# LPC5410x register map
File version: 0.4
CPU: CM4 r0p0, little endian, no MPU, no FPU, 0x3 interrupt priority bits, 0x0 interrupts
Registers are 32-bit, read-write, reset 0x0 unless marked. A register's access mark holds for its fields unless they carry their own. Offsets are from the block's base; [hi:lo] are bit positions; {n}, {i} and the like mark numbered series.

## SYSCON — System configuration
Base 0x40000000
0x00 SYSMEMREMAP — System memory remap
  [1:0] MAP — System memory remap. Value 0x3 is reserved.
    0=BOOT_LOADER_MODE (Boot Loader Mode. Interrupt vectors are re-mapped to Boot ROM.); 1=USER_RAM_MODE (User RAM Mode. Interrupt vectors are re-mapped to Static RAM.); 2=USER_FLASH_MODE (User Flash Mode. Interrupt vectors are not re-mapped and reside in Flash.)
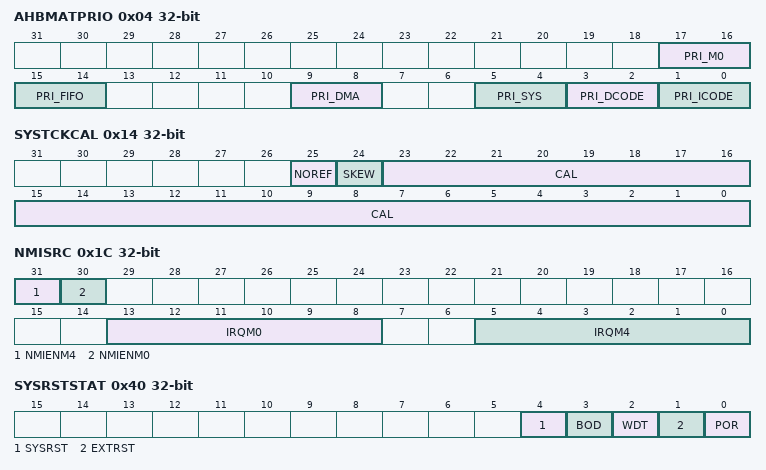
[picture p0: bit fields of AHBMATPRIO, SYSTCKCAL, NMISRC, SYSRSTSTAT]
0x04 AHBMATPRIO — AHB multilayer matrix priority control
  [17:16] PRI_M0 — Cortex-M0+ bus priority.
  [15:14] PRI_FIFO — System FIFO bus priority
  [9:8] PRI_DMA — DMA controller priority.
  [5:4] PRI_SYS — System bus priority.
  [3:2] PRI_DCODE — D-Code bus priority.
  [1:0] PRI_ICODE — I-Code bus priority. Should be lower than PRI_DCODE for proper operation.
0x14 SYSTCKCAL — System tick counter calibration
  [25] NOREF — Initial value for the Systick timer.
  [24] SKEW — Initial value for the Systick timer.
  [23:0] CAL — System tick timer calibration value.
0x1C NMISRC — NMI Source Select
  [31] NMIENM4 — Write a 1 to this bit to enable the Non-Maskable Interrupt (NMI) source selected by IRQM4.
  [30] NMIENM0 — Write a 1 to this bit to enable the Non-Maskable Interrupt (NMI) source selected by IRQM0.
  [13:8] IRQM0 — The IRQ number of the interrupt that acts as the Non-Maskable Interrupt (NMI) for the Cortex-M0+, if enabled by NMIENM0.
  [5:0] IRQM4 — The IRQ number of the interrupt that acts as the Non-Maskable Interrupt (NMI) for the Cortex-M4, if enabled by NMIENM4.
0x20 ASYNCAPBCTRL reset 0x1 — Asynchronous APB Control
  [0] ENABLE — Enables the asynchronous APB bridge and subsystem.
    0=DISABLED (Disabled. Asynchronous APB bridge is disabled.); 1=ENABLED (Enabled. Asynchronous APB bridge is enabled.)
0x40 SYSRSTSTAT — System reset status register
  [4] SYSRST — Status of the software system reset
    0=NO_SYSTEM_RESET_DETE (No System reset detected); 1=SYSTEM_RESET_DETECTE (System reset detected. Writing a one clears this reset.)
  [3] BOD — Status of the Brown-out detect reset
    0=NO_BOD_RESET_DETECTE (No BOD reset detected); 1=BOD_RESET_DETECTED (BOD reset detected. Writing a one clears this reset.)
  [2] WDT — Status of the Watchdog reset
    0=NO_WDT_RESET_DETECTE (No WDT reset detected); 1=WDT_RESET_DETECTED (WDT reset detected. Writing a one clears this reset.)
  [1] EXTRST — Status of the external RESET pin. External reset status.
    0=NO_RESET_EVENT_DETEC (No reset event detected.); 1=RESET_DETECTED (Reset detected. Writing a one clears this reset.)
  [0] POR — POR reset status
    0=NO_POR_DETECTED; 1=POR_DETECTED (POR detected. Writing a one clears this reset.)
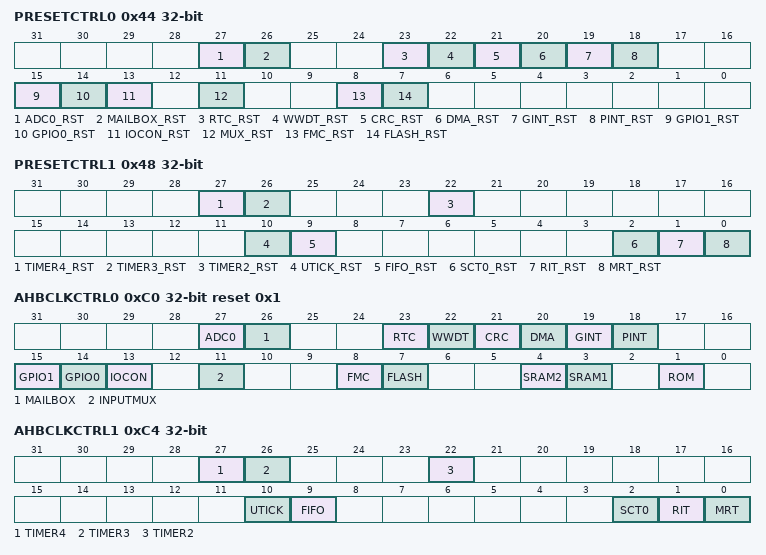
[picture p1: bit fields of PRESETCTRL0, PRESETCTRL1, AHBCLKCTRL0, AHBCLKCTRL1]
0x44 PRESETCTRL0 — Peripheral reset control 0
  [27] ADC0_RST — ADC0 reset control. 0 = Clear reset to this function. 1 = Assert reset to this function.
  [26] MAILBOX_RST — Mailbox reset control. 0 = Clear reset to this function. 1 = Assert reset to this function.
  [23] RTC_RST — RTC reset control. 0 = Clear reset to this function. 1 = Assert reset to this function.
  [22] WWDT_RST — Watchdog timer reset control. 0 = Clear reset to this function. 1 = Assert reset to this function.
  [21] CRC_RST — CRC generator reset control. 0 = Clear reset to this function. 1 = Assert reset to this function.
  [20] DMA_RST — DMA reset control. 0 = Clear reset to this function. 1 = Assert reset to this function.
  [19] GINT_RST — Grouped interrupt (GINT) reset control. 0 = Clear reset to this function. 1 = Assert reset to this function.
  [18] PINT_RST — Pin interrupt (PINT) reset control. 0 = Clear reset to this function. 1 = Assert reset to this function.
  [15] GPIO1_RST — GPIO1 reset control. 0 = Clear reset to this function. 1 = Assert reset to this function.
  [14] GPIO0_RST — GPIO0 reset control. 0 = Clear reset to this function. 1 = Assert reset to this function.
  [13] IOCON_RST — IOCON reset control. 0 = Clear reset to this function. 1 = Assert reset to this function.
  [11] MUX_RST — Input mux reset control. 0 = Clear reset to this function. 1 = Assert reset to this function.
  [8] FMC_RST — Flash accelerator reset control. 0 = Clear reset to this function. 1 = Assert reset to this function.
  [7] FLASH_RST — Flash controller reset control. 0 = Clear reset to this function. 1 = Assert reset to this function.
0x48 PRESETCTRL1 — Peripheral reset control 1
  [27] TIMER4_RST — Timer 4 reset control. 0 = Clear reset to this function. 1 = Assert reset to this function.
  [26] TIMER3_RST — Timer 3 reset control. 0 = Clear reset to this function. 1 = Assert reset to this function.
  [22] TIMER2_RST — Timer 2 reset control. 0 = Clear reset to this function. 1 = Assert reset to this function.
  [10] UTICK_RST — Micro-tick Timer reset control. 0 = Clear reset to this function. 1 = Assert reset to this function.
  [9] FIFO_RST — System FIFO reset control. 0 = Clear reset to this function. 1 = Assert reset to this function.
  [2] SCT0_RST — State configurable timer 0 (SCT0) reset control. 0 = Clear reset to this function. 1 = Assert reset to this function.
  [1] RIT_RST — Repetitive interrupt timer (RIT) reset control. 0 = Clear reset to this function. 1 = Assert reset to this function.
  [0] MRT_RST — Multi-rate timer (MRT) reset control. 0 = Clear reset to this function. 1 = Assert reset to this function.
0x4C PRESETCTRLSET0 wo reset not defined — Set bits in PRESETCTRL0
  [31:0] RST_SET0 — Writing ones to this register sets the corresponding bit or bits in the PRESETCTRL0 register, if they are implemented. Bits that do not correspond to defined bits in PRESETCTRL0 are reserved and only zeroes should be written to them.
0x50 PRESETCTRLSET1 wo reset not defined — Set bits in PRESETCTRL1
  [31:0] RST_SET1 — Writing ones to this register sets the corresponding bit or bits in the PRESETCTRL1 register, if they are implemented. Bits that do not correspond to defined bits in PRESETCTRL1 are reserved and only zeroes should be written to them.
0x54 PRESETCTRLCLR0 wo reset not defined — Clear bits in PRESETCTRL0
  [31:0] RST_CLR0 — Writing ones to this register clears the corresponding bit or bits in the PRESETCTRL0 register, if they are implemented. Bits that do not correspond to defined bits in PRESETCTRL0 are reserved and only zeroes should be written to them.
0x58 PRESETCTRLCLR1 wo reset not defined — Clear bits in PRESETCTRL1
  [31:0] RST_CLR1 — Writing ones to this register clears the corresponding bit or bits in the PRESETCTRL1 register, if they are implemented. Bits that do not correspond to defined bits in PRESETCTRL1 are reserved and only zeroes should be written to them.
0x5C PIOPORCAP0 ro reset not defined — POR captured PIO status 0
  [31:0] PIOPORSTAT — State of PIO0_31 through PIO0_0 at power-on reset
0x60 PIOPORCAP1 ro reset not defined — POR captured PIO status 1
  [31:0] PIOPORSTAT — State of PIO1_31 through PIO1_0 at power-on reset
0x68 PIORESCAP0 ro reset not defined — Reset captured PIO status 0
  [31:0] PIORESSTAT — State of PIO0_31 through PIO0_0 for resets other than power-on reset.
0x6C PIORESCAP1 ro reset not defined — Reset captured PIO status 1
  [31:0] PIORESSTAT — State of PIO1_31 through PIO1_0 for resets other than power-on reset.
0x80 MAINCLKSELA — Main clock source select A
  [1:0] SEL — Clock source for main clock source selector A
    0=IRC_OSCILLATOR; 1=CLKIN; 2=WATCHDOG_OSCILLATOR
0x84 MAINCLKSELB — Main clock source select B
  [1:0] SEL — Clock source for main clock source selector B. Selects the clock source for the main clock.
    0=MAINCLKSELA (MAINCLKSELA. Use the clock source selected in MAINCLKSELA register.); 1=SYSTEM_PLL_INPUT; 2=SYSTEM_PLL_OUTPUT; 3=RTC_OSC_OUTPUT (RTC osc output. RTC oscillator 32 kHz output.)
0x8C ADCCLKSEL — ADC clock source select
  [1:0] SEL — ADC clock source.
    0=MAIN_CLOCK; 1=SYSTEM_PLL_OUTPUT; 2=IRC_OSCILLATOR
0x94 CLKOUTSELA — CLKOUT clock source select A
  [1:0] SEL — CLKOUT clock source
    0=MAIN_CLOCK; 1=CLKIN; 2=WATCHDOG_OSCILLATOR; 3=IRC_OSCILLATOR
0x98 CLKOUTSELB — CLKOUT clock source select B
  [1:0] SEL — CLKOUT clock source
    0=CLKOUTSELA (CLKOUTSELA. Clock source selected in the CLKOUTSELA register.); 3=RTC_32_KHZ_CLOCK
0xA0 SYSPLLCLKSEL — PLL clock source select
  [1:0] SEL — System PLL clock source
    0=IRC_OSCILLATOR; 1=CLKIN; 2=WATCHDOG_OSCILLATOR; 3=RTC_32_KHZ_CLOCK
0xC0 AHBCLKCTRL0 reset 0x1 — AHB Clock control 0
  [27] ADC0 — Enables the clock for the ADC0 register interface. 0 = Disable; 1 = Enable.
  [26] MAILBOX — Enables the clock for the Mailbox. 0 = Disable; 1 = Enable.
  [23] RTC — Enables the clock for the RTC. 0 = Disable; 1 = Enable.
  [22] WWDT — Enables the clock for the Watchdog Timer. 0 = Disable; 1 = Enable.
  [21] CRC — Enables the clock for the CRC engine. 0 = Disable; 1 = Enable.
  [20] DMA — Enables the clock for the DMA controller. 0 = Disable; 1 = Enable.
  [19] GINT — Enables the clock for the grouped pin interrupt block. 0 = Disable; 1 = Enable.
  [18] PINT — Enables the clock for the pin interrupt block.0 = Disable; 1 = Enable.
  [15] GPIO1 — Enables the clock for the GPIO1 port registers. 0 = Disable; 1 = Enable.
  [14] GPIO0 — Enables the clock for the GPIO0 port registers. 0 = Disable; 1 = Enable.
  [13] IOCON — Enables the clock for the IOCON block. 0 = Disable; 1 = Enable.
  [11] INPUTMUX — Enables the clock for the input muxes. 0 = Disable; 1 = Enable.
  [8] FMC — Enables the clock for the Flash accelerator. 0 = Disable; 1 = Enable.
  [7] FLASH — Enables the clock for the flash controller. 0 = Disable; 1 = Enable.
  [4] SRAM2 — Enables the clock for SRAM2. 0 = Disable; 1 = Enable.
  [3] SRAM1 — Enables the clock for SRAM1. 0 = Disable; 1 = Enable.
  [1] ROM — Enables the clock for the Boot ROM. 0 = Disable; 1 = Enable.
0xC4 AHBCLKCTRL1 — AHB Clock control 1
  [27] TIMER4 — Enables the clock for Timer 4. 0 = Disable; 1 = Enable.
  [26] TIMER3 — Enables the clock for Timer 3. 0 = Disable; 1 = Enable.
  [22] TIMER2 — Enables the clock for Timer 2. 0 = Disable; 1 = Enable.
  [10] UTICK — Enables the clock for the Micro-tick Timer. 0 = Disable; 1 = Enable.
  [9] FIFO — Enables the clock for system FIFOs. 0 = Disable; 1 = Enable.
  [2] SCT0 — Enables the clock for SCT0. 0 = Disable; 1 = Enable.
  [1] RIT — Enables the clock for the repetitive interrupt timer. 0 = Disable; 1 = Enable.
  [0] MRT — Enables the clock for the Multi-Rate Timer. 0 = Disable; 1 = Enable.
0xC8 AHBCLKCTRLSET0 wo reset not defined — Set bits in AHBCLKCTRL0
  [31:0] CLK_SET0 — Writing ones to this register sets the corresponding bit or bits in the AHBCLKCTRL0 register, if they are implemented. Bits that do not correspond to defined bits in AHBCLKCTRL0 are reserved and only zeroes should be written to them.
0xCC AHBCLKCTRLSET1 wo reset not defined — Set bits in AHBCLKCTRL1
  [31:0] CLK_SET1 — Writing ones to this register sets the corresponding bit or bits in the AHBCLKCTRL1 register, if they are implemented. Bits that do not correspond to defined bits in AHBCLKCTRL1 are reserved and only zeroes should be written to them.
0xD0 AHBCLKCTRLCLR0 wo reset not defined — Clear bits in AHBCLKCTRL0
  [31:0] CLK_CLR0 — Writing ones to this register clears the corresponding bit or bits in the AHBCLKCTRL0 register, if they are implemented. Bits that do not correspond to defined bits in AHBCLKCTRL0 are reserved and only zeroes should be written to them.
0xD4 AHBCLKCTRLCLR1 wo reset not defined — Clear bits in AHBCLKCTRL1
  [31:0] CLK_CLR1 — Writing ones to this register clears the corresponding bit or bits in the AHBCLKCTRL1 register, if they are implemented. Bits that do not correspond to defined bits in AHBCLKCTRL1 are reserved and only zeroes should be written to them.
0xE0 SYSTICKCLKDIV — SYSTICK clock divider
  [7:0] DIV — SYSTICK clock divider value. 0: Disable SYSTICK timer clock. 1: Divide by 1. to 255: Divide by 255.
0x100 AHBCLKDIV reset 0x1 — System clock divider
  [7:0] DIV — System AHB clock divider value. 0: System clock disabled. 1: Divide by 1. to 255: Divide by 255.
0x108 ADCCLKDIV — ADC clock divider
  [7:0] DIV — ADC clock divider value. 0: Disable ADC clock. 1: Divide by 1. to 255: Divide by 255.
0x10C CLKOUTDIV — CLKOUT clock divider
  [7:0] DIV — CLKOUT clock divider value. 0: Disable CLKOUT clock divider. 1: Divide by 1. to 255: Divide by 255.
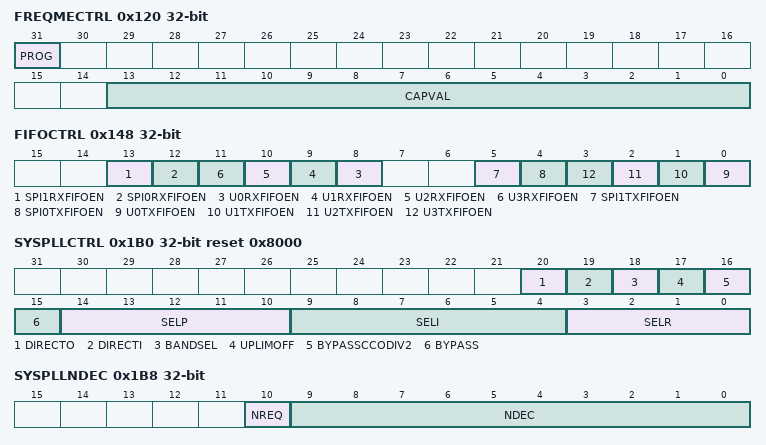
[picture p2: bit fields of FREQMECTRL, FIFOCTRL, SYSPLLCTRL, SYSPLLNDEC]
0x120 FREQMECTRL — Frequency measure register
  [31] PROG — Set this bit to one to initiate a frequency measurement cycle. Hardware clears this bit when the measurement cycle has completed and there is valid capture data in the CAPVAL field (bits 13:0).
  [13:0] CAPVAL — Stores the capture result which is used to calculate the frequency of the target clock. This field is read-only.
0x124 FLASHCFG reset 0x5000 — Flash wait states configuration
  [14:12] FLASHTIM — Flash memory access time. FLASHTIM +1 is equal to the number of system clocks used for flash access.
    0=1_CLOCK_CYCLE (1 clock cycle. 1 system clock flash access time (for system clock frequencies of up to MHz).); 1=2_CLOCK_CYCLES (2 clock cycles. 2 system clocks flash access time (for system clock frequencies of up to MHz).); 2=3_CLOCK_CYCLES (3 clock cycles. 3 system clocks flash access time (for system clock frequencies of up to MHz).); {v}={v+1}_CLOCK_CYCLES ({v+1} clock cycles. {v+1} system clocks flash access time.) (v=3..7)
0x148 FIFOCTRL — Serial interface FIFO enables
  [13] SPI1RXFIFOEN — SPI1 receiver FIFO enable
  [12] SPI0RXFIFOEN — SPI0 receiver FIFO enable
  [n+8] U{n}RXFIFOEN (n=0..3) — USART{n} receiver FIFO enable
  [5] SPI1TXFIFOEN — SPI1 transmitter FIFO enable
  [4] SPI0TXFIFOEN — SPI0 transmitter FIFO enable
  [n] U{n}TXFIFOEN (n=0..3) — USART{n} transmitter FIFO enable
0x184 IRCCTRL reset 0x80 — IRC oscillator control
  [7:0] TRIM — Trim value
0x190 RTCOSCCTRL reset 0x1 — RTC oscillator 32 kHz output control
  [0] EN — RTC 32 kHz clock enable.
    0=DISABLED (Disabled. RTC clock off.); 1=ENABLED (Enabled. RTC clock on.)
0x1B0 SYSPLLCTRL reset 0x8000 — PLL control
  [20] DIRECTO — PLL0 direct output enable
    0=DISABLED (Disabled. The PLL output divider (P divider) is used to create the PLL output.); 1=ENABLED (Enabled. The PLL output divider (P divider) is bypassed, the PLL CCO output is used as the PLL output.)
  [19] DIRECTI — PLL0 direct input enable
    0=DISABLED (Disabled. The PLL input divider (N divider) output is used to drive the PLL CCO.); 1=ENABLED (Enabled. The PLL input divider (N divider) is bypassed. the PLL input clock is used directly to drive the PLL CCO.)
  [18] BANDSEL — PLL filter control. Set this bit to one when the SSGC is disabled or at low frequencies.
    0=SSCG_CONTROL (SSCG control. The PLL filter uses the parameters derived from the SSCG decoder.); 1=MDEC_CONTROL (MDEC control. The PLL filter uses the programmable fields SELP, SELR, and SELI in this register to control the filter constants.)
  [17] UPLIMOFF — Enable spread spectrum/fractional mode
    0=NORMAL_MODE; 1=SSGC_MODE (SSGC mode. Spread spectrum/fractional mode.)
  [16] BYPASSCCODIV2 — Bypass feedback clock divide by 2.
    0=DIVIDE_BY_2 (Divide by 2. The CCO feedback clock is divided by 2 in addition to the programmed M divide.); 1=BYPASS (Bypass. The CCO feedback clock is divided only by the programmed M divide.)
  [15] BYPASS — PLL bypass control
    0=DISABLED (Disabled. PLL CCO is used to create the PLL output.); 1=ENABLED (Enabled. PLL is bypassed, the PLL input clock is routed directly to the PLL output (default).)
  [14:10] SELP — Bandwidth select P value
  [9:4] SELI — Bandwidth select I value
  [3:0] SELR — Bandwidth select R value
0x1B4 SYSPLLSTAT ro — PLL status
  [0] LOCK — PLL0 lock indicator
0x1B8 SYSPLLNDEC — PLL N decoder
  [10] NREQ — NDEC reload request. When a 1 is written to this bit, the NDEC value is loaded into the PLL. Must be cleared by software for any subsequent load, or the PLL can be powered down and back up via the PDEN_SYS_PLL bit in the PDRUNCFG register if the NDEC value is changed.
  [9:0] NDEC — Decoded N-divider coefficient value
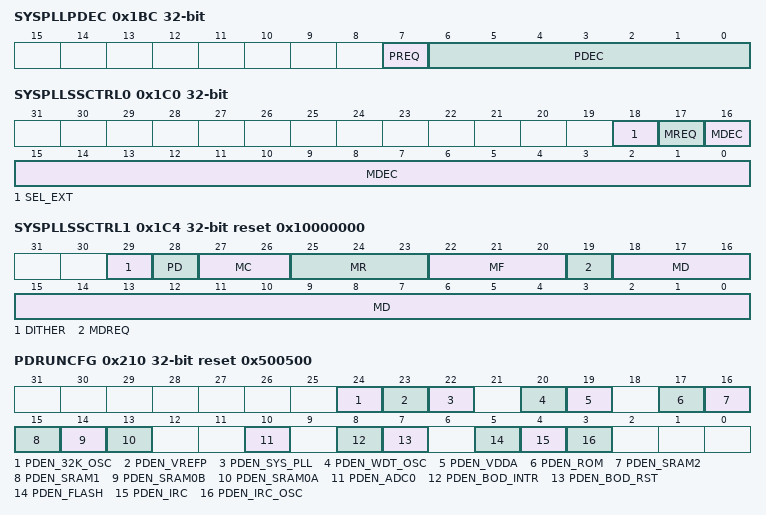
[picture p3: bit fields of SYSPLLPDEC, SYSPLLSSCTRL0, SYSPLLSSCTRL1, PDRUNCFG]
0x1BC SYSPLLPDEC — PLL P decoder
  [7] PREQ — PDEC reload request. When a 1 is written to this bit, the PDEC value is loaded into the PLL. Must be cleared by software for any subsequent load, or the PLL can be powered down and back up via the PDEN_SYS_PLL bit in the PDRUNCFG register if the PDEC value is changed.
  [6:0] PDEC — Decoded P-divider coefficient value
0x1C0 SYSPLLSSCTRL0 — PLL spread spectrum control 0
  [18] SEL_EXT — Select spread spectrum mode.
    0=SPREAD_SPECTRUM_MODE (Spread spectrum mode. Spread spectrum mode enabled.); 1=MDEC_ENABLED (MDEC enabled. Spread spectrum clock generator not used.)
  [17] MREQ — MDEC reload request. When a 1 is written to this bit, the MDEC value is loaded into the PLL. Must be cleared by software for any subsequent load, or the PLL can be powered down and back up via the PDEN_SYS_PLL bit in the PDRUNCFG register if the MDEC value is changed.
  [16:0] MDEC — Decoded M-divider coefficient value
0x1C4 SYSPLLSSCTRL1 reset 0x10000000 — PLL spread spectrum control 1
  [29] DITHER — Select modulation frequency.
    0=FIXED (Fixed. Fixed modulation frequency.); 1=DITHER (Dither. Randomly dither between two modulation frequencies.)
  [28] PD — Power down.
    0=ENABLED (Enabled. Spread spectrum controller is enabled); 1=DISABLED (Disabled. Spread spectrum controller is disabled)
  [27:26] MC — Modulation waveform control 0 = no compensation Compensation for low pass filtering of the PLL to get a triangular modulation at the output of the PLL, giving a flat frequency spectrum. 0b00 => no compensation 0b10 => recommended setting 0b11 => max. compensation
  [25:23] MR — Programmable frequency modulation depth deltafmodpk-pk = Fref x k/Fcco = k/MDdec 0 = no spread 0b000 => k = 0 (no spread spectrum) 0b001 => k = 1 0b010 => k = 1.5 0b011 => k = 2 0b100 => k = 3 0b101 => k = 4 0b110 => k = 6 0b111 => k = 8
  [22:20] MF — Programmable modulation frequency fm = Fref/Nss with Fref = Fin/N 0b000 => Nss = 512 (fm = 3.9 - 7.8 kHz) 0b001 => Nss = 384 (fm = 5.2 - 10.4 kHz) 0b010 => Nss = 256 (fm = 7.8 - 15.6 kHz) 0b011 => Nss = 128 (fm = 15.6 - 31.3 kHz) 0b100 => Nss = 64 (fm = 32.3 - 64.5 kHz) 0b101 => Nss = 32 (fm = 62.5- 125 kHz) 0b110 => Nss = 24 (fm = 83.3- 166.6 kHz) 0b111 => Nss = 16 (fm = 125- 250 kHz)
  [19] MDREQ — MD reload request. When a 1 is written to this bit, the MD value is loaded into the PLL. This bit is cleared when the load is complete.
  [18:0] MD — M- divider value with fraction. MD[18:11] : integer portion of the feedback divider value. MD[10:0] : fractional portion of the feedback divider value.
0x210 PDRUNCFG reset 0x500500 — Power configuration register
  [24] PDEN_32K_OSC — 32 kHz RTC oscillator. 0 = Powered; 1 = Powered down.
  [23] PDEN_VREFP — Vrefp to the ADC, must be enabled for the ADC to work. Also see bit 19. 0 = Powered; 1 = Powered down.
  [22] PDEN_SYS_PLL — PLL0. 0 = Powered; 1 = Powered down.
  [20] PDEN_WDT_OSC — Watchdog oscillator. 0 = Powered; 1 = Powered down.
  [19] PDEN_VDDA — Vdda to the ADC, must be enabled for the ADC to work. Also see bit 23. 0 = Powered; 1 = Powered down.
  [17] PDEN_ROM — ROM. 0 = Powered; 1 = Powered down.
  [16] PDEN_SRAM2 — SRAM2 (undedicated 8 kB RAM). 0 = Powered; 1 = Powered down.
  [15] PDEN_SRAM1 — SRAM1. 0 = Powered; 1 = Powered down.
  [14] PDEN_SRAM0B — Remaining portion of SRAM0). 0 = Powered; 1 = Powered down.
  [13] PDEN_SRAM0A — First 8 kB of SRAM0). 0 = Powered; 1 = Powered down.
  [10] PDEN_ADC0 — ADC0. 0 = Powered; 1 = Powered down.
  [8] PDEN_BOD_INTR — Brown-out Detect interrupt. 0 = Powered; 1 = Powered down.
  [7] PDEN_BOD_RST — Brown-out Detect reset. 0 = Powered; 1 = Powered down.
  [5] PDEN_FLASH — Flash memory. 0 = Powered; 1 = Powered down.
  [4] PDEN_IRC — IRC oscillator. 0 = Powered; 1 = Powered down.
  [3] PDEN_IRC_OSC — IRC oscillator output. 0 = Powered; 1 = Powered down.
0x214 PDRUNCFGSET wo reset not defined — Set bits in PDRUNCFG
  [31:0] PD_SET — Writing ones to this register sets the corresponding bit or bits in the PDRUNCFG register, if they are implemented. Bits that do not correspond to defined bits in PDRUNCFG are reserved and only zeroes should be written to them.
0x218 PDRUNCFGCLR wo reset not defined — Clear bits in PDRUNCFG
  [31:0] PD_CLR — Writing ones to this register clears the corresponding bit or bits in the PDRUNCFG register, if they are implemented. Bits that do not correspond to defined bits in PDRUNCFG are reserved and only zeroes should be written to them.
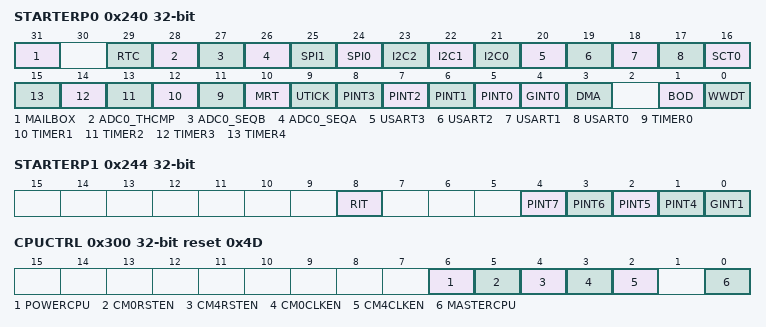
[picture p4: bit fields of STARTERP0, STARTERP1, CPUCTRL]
0x240 STARTERP0 — Start logic 0 wake-up enable register
  [31] MAILBOX — Mailbox interrupt wake-up. 0 = Wake-up disabled. 1 = Wake-up enabled.Typically used in sleep mode only.
  [29] RTC — RTC interrupt wake-up. 0 = Wake-up disabled. 1 = Wake-up enabled.
  [28] ADC0_THCMP — ADC0 threshold and error interrupt wake-up. 0 = Wake-up disabled. 1 = Wake-up enabled.Typically used in sleep mode only.
  [27] ADC0_SEQB — ADC0 sequence B interrupt wake-up. 0 = Wake-up disabled. 1 = Wake-up enabled.Typically used in sleep mode only.
  [26] ADC0_SEQA — ADC0 sequence A interrupt wake-up. 0 = Wake-up disabled. 1 = Wake-up enabled.Typically used in sleep mode only.
  [25] SPI1 — SPI1 interrupt wake-up. 0 = Wake-up disabled. 1 = Wake-up enabled. Peripheral interrupt.
  [24] SPI0 — SPI0 interrupt wake-up. 0 = Wake-up disabled. 1 = Wake-up enabled. Peripheral interrupt.
  [23] I2C2 — I2C2 interrupt wake-up. 0 = Wake-up disabled. 1 = Wake-up enabled. Peripheral interrupt.
  [22] I2C1 — I2C1 interrupt wake-up. 0 = Wake-up disabled. 1 = Wake-up enabled. Peripheral interrupt.
  [21] I2C0 — I2C0 interrupt wake-up. 0 = Wake-up disabled. 1 = Wake-up enabled. Peripheral interrupt.
  [20] USART3 — USART2 interrupt wake-up. 0 = Wake-up disabled. 1 = Wake-up enabled. Peripheral interrupt.
  [19] USART2 — USART2 interrupt wake-up. 0 = Wake-up disabled. 1 = Wake-up enabled. Peripheral interrupt.
  [18] USART1 — USART1 interrupt wake-up. 0 = Wake-up disabled. 1 = Wake-up enabled. Peripheral interrupt.
  [17] USART0 — USART0 interrupt wake-up. 0 = Wake-up disabled. 1 = Wake-up enabled. Peripheral interrupt.
  [16] SCT0 — SCT0 wake-up. 0 = Wake-up disabled. 1 = Wake-up enabled.Typically used in sleep mode only.
  [n+11] TIMER{n} (n=0..4) — Timer {n} wake-up. 0 = Wake-up disabled. 1 = Wake-up enabled.Typically used in sleep mode only.
  [10] MRT — Multi-Rate Timer wake-up. 0 = Wake-up disabled. 1 = Wake-up enabled. Typically used in sleep mode only.
  [9] UTICK — Micro-tick Timer wake-up. 0 = Wake-up disabled. 1 = Wake-up enabled.
  [n+5] PINT{n} (n=0..3) — GPIO pin interrupt {n} wake-up. 0 = Wake-up disabled. 1 = Wake-up enabled. Not for pattern match.
  [4] GINT0 — Group interrupt 0 wake-up. 0 = Wake-up disabled. 1 = Wake-up enabled.
  [3] DMA — DMA wake-up. 0 = Wake-up disabled. 1 = Wake-up enabled. Typically used in sleep mode only.
  [1] BOD — BOD interrupt wake-up. 0 = Wake-up disabled. 1 = Wake-up enabled.
  [0] WWDT — WWDT interrupt wake-up. 0 = Wake-up disabled. 1 = Wake-up enabled.
0x244 STARTERP1 — Start logic 1 wake-up enable register
  [8] RIT — Repetitive Interrupt Timer interrupt wake-up. 0 = Wake-up disabled. 1 = Wake-up enabled. Typically used in sleep mode only.
  [n-3] PINT{n} (n=4..7) — GPIO pin interrupt {n} wake-up. 0 = Wake-up disabled. 1 = Wake-up enabled. Not for pattern match.
  [0] GINT1 — Group interrupt 0 wake-up. 0 = Wake-up disabled. 1 = Wake-up enabled.
0x248 STARTERPSET0 wo reset not defined — Set bits in STARTERP0
  [31:0] START_SET0 — Writing ones to this register sets the corresponding bit or bits in the STARTERP0 register, if they are implemented. Bits that do not correspond to defined bits in STARTERP0 are reserved and only zeroes should be written to them.
0x24C STARTERPSET1 wo reset not defined — Set bits in STARTERP1
  [31:0] START_SET1 — Writing ones to this register sets the corresponding bit or bits in the STARTERP1 register, if they are implemented. Bits that do not correspond to defined bits in STARTERP1 are reserved and only zeroes should be written to them.
0x250 STARTERPCLR0 wo reset not defined — Clear bits in STARTERP0
  [31:0] START_CLR0 — Writing ones to this register clears the corresponding bit or bits in the STARTERP0 register, if they are implemented. Bits that do not correspond to defined bits in STARTERP0 are reserved and only zeroes should be written to them.
0x254 STARTERPCLR1 wo reset not defined — Clear bits in STARTERP1
  [31:0] START_CLR1 — Writing ones to this register clears the corresponding bit or bits in the STARTERP1 register, if they are implemented. Bits that do not correspond to defined bits in STARTERP1 are reserved and only zeroes should be written to them.
0x300 CPUCTRL reset 0x4D — CPU Control for multiple processors
  [6] POWERCPU — Identifies the owner of reduced power mode control: which CPU can cause the device to enter Sleep, Deep Sleep, Power-down, and Deep Power-down modes.
    0=M0P (M0+. Cortex-M0+ is the owner of reduced power mode control.); 1=M4 (M4. Cortex-M4 is the owner of reduced power mode control.)
  [5] CM0RSTEN — Cortex-M0+ reset.
    0=DISABLED (Disabled. The Cortex-M0+ is not being reset.); 1=ENABLED (Enabled. The Cortex-M0+ is being reset.)
  [4] CM4RSTEN — Cortex-M4 reset.
    0=DISABLED (Disabled. The Cortex-M4 is not being reset.); 1=ENABLED (Enabled. The Cortex-M4 is being reset.)
  [3] CM0CLKEN — Cortex-M0+ clock enable.
    0=DISABLED (Disabled. The Cortex-M0+ clock is not enabled.); 1=ENABLED (Enabled. The Cortex-M0+ clock is enabled.)
  [2] CM4CLKEN — Cortex-M4 clock enable.
    0=DISABLED (Disabled. The Cortex-M4 clock is not enabled.); 1=ENABLED (Enabled. The Cortex-M4 clock is enabled.)
  [0] MASTERCPU — Determines which CPU is considered the master. The master CPU cannot have its clock turned off via the related CMnCLKEN bit or be reset via the related CMxRSTEN in this register. The slave CPU wakes up briefly following device reset, then goes back to sleep until activated by the master CPU.
    0=M0P (M0+. Cortex-M0+ is the master CPU.); 1=M4 (M4. Cortex-M4 is the master CPU.)
0x304 CPBOOT — Coprocessor Boot Address
  [31:0] BOOTADDR — Slave processor boot address.
0x308 CPSTACK — Coprocessor Stack Address
  [31:0] STACKADDR — Slave processor stack address.
0x3F4 JTAGIDCODE ro reset not defined
  [31:0] JTAGID — JTAG ID code.
0x3F8 DEVICE_ID0 ro reset not defined — Part ID register
  [31:0] PARTID
0x3FC DEVICE_ID1 ro reset not defined — Boot ROM and die revision register
  [31:0] REVID — Revision.
